# ATSAMR21E18A device description
Architecture: CORTEX-M0PLUS; Family: SAMR; Series: SAMR21
Registers are 32-bit, read-write, reset 0x0 unless marked. A register's access mark holds for its fields unless they carry their own. Offsets are from the block's base; [hi:lo] are bit positions; lines under a group give offsets from that group; {n}, {i} and the like mark numbered series; 'fields as' and 'values as' point back to an identical list; <NAME> marks a mode.

## RFCTRL — RF233 control module
Instances: RFCTRL 0x42005400
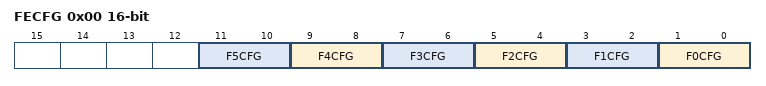
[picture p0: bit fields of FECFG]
0x00 FECFG 16-bit — Front-end control bus configuration
  [2n+1:2n] F{n}CFG (n=0..5) — Front-end control signal {n} configuration

## USB_DESCRIPTOR — Universal Serial Bus
Modes: DEVICE when USB.CTRLA.MODE=0 (USB is Device); HOST when USB.CTRLA.MODE=1 (USB is Host)
{0x0+0x10*i} DEVICE_DESC_BANK[{i}] (i=0..1) <DEVICE> group
  0x00 ADDR <DEVICE> reset not defined — DEVICE_DESC_BANK Endpoint Bank, Adress of Data Buffer
    [31:0] ADDR — Adress of data buffer
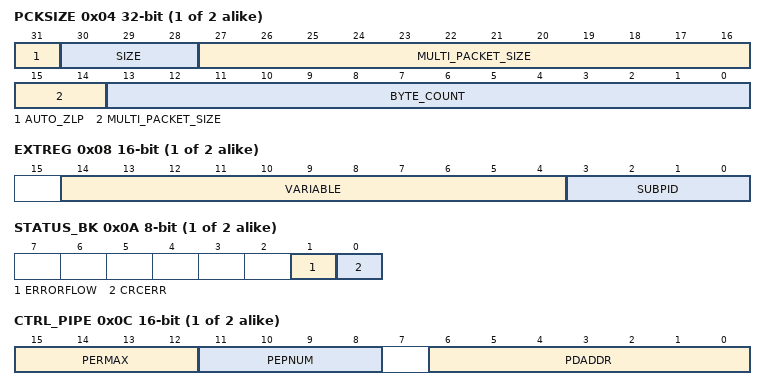
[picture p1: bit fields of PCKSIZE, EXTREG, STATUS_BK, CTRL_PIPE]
  0x04 PCKSIZE <DEVICE> reset not defined — DEVICE_DESC_BANK Endpoint Bank, Packet Size
    [31] AUTO_ZLP — Automatic Zero Length Packet
    [30:28] SIZE — Enpoint size
    [27:14] MULTI_PACKET_SIZE — Multi Packet In or Out size
    [13:0] BYTE_COUNT
  0x08 EXTREG <DEVICE> 16-bit reset not defined — DEVICE_DESC_BANK Endpoint Bank, Extended
    [14:4] VARIABLE — Variable field send with extended token
    [3:0] SUBPID — SUBPID field send with extended token
  0x0A STATUS_BK <DEVICE> 8-bit reset not defined — DEVICE_DESC_BANK Enpoint Bank, Status of Bank
    [1] ERRORFLOW — Error Flow Status
    [0] CRCERR — CRC Error Status
{0x0+0x10*i} HOST_DESC_BANK[{i}] (i=0..1) <HOST> group
  0x00 ADDR <HOST> reset not defined — HOST_DESC_BANK Host Bank, Adress of Data Buffer
    [31:0] ADDR — Adress of data buffer
  0x04 PCKSIZE <HOST> reset not defined — HOST_DESC_BANK Host Bank, Packet Size
    [31] AUTO_ZLP — Automatic Zero Length Packet
    [30:28] SIZE — Pipe size
    [27:14] MULTI_PACKET_SIZE — Multi Packet In or Out size
    [13:0] BYTE_COUNT
  0x08 EXTREG <HOST> 16-bit reset not defined — HOST_DESC_BANK Host Bank, Extended
    fields as DEVICE_DESC_BANK[0]<DEVICE>.EXTREG<DEVICE>
  0x0A STATUS_BK <HOST> 8-bit reset not defined — HOST_DESC_BANK Host Bank, Status of Bank
    [1] ERRORFLOW — Error Flow Status
    [0] CRCERR — CRC Error Status
  0x0C CTRL_PIPE <HOST> 16-bit — HOST_DESC_BANK Host Bank, Host Control Pipe
    [15:12] PERMAX — Pipe Error Max Number
    [11:8] PEPNUM — Pipe Endpoint Number
    [6:0] PDADDR — Pipe Device Adress
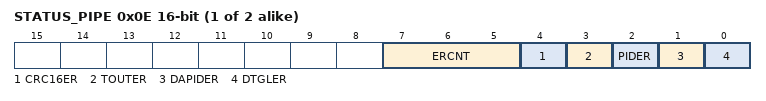
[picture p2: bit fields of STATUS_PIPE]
  0x0E STATUS_PIPE <HOST> 16-bit reset not defined — HOST_DESC_BANK Host Bank, Host Status Pipe
    [7:5] ERCNT — Pipe Error Count
    [4] CRC16ER — CRC16 Error
    [3] TOUTER — Time Out Error
    [2] PIDER — PID Error
    [1] DAPIDER — Data PID Error
    [0] DTGLER — Data Toggle Error

## WDT — Watchdog Timer
Instances: WDT 0x40001000
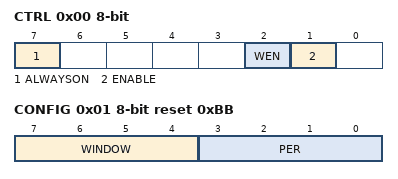
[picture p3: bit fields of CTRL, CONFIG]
0x00 CTRL 8-bit (WSYNC) — Control
  [7] ALWAYSON
  [2] WEN — Watchdog Timer Window Mode Enable
  [1] ENABLE
0x01 CONFIG 8-bit reset 0xBB (WSYNC) — Configuration
  [7:4] WINDOW — Window Mode Time-Out Period
    0=8 clock cycles; 1=16 clock cycles; 2=32 clock cycles; 3=64 clock cycles; 4=128 clock cycles; 5=256 clock cycles; 6=512 clock cycles; 7=1K (1024 clock cycles); 8=2K (2048 clock cycles); 9=4K (4096 clock cycles); 10=8K (8192 clock cycles); 11=16K (16384 clock cycles)
  [3:0] PER — Time-Out Period
    values as WINDOW
0x02 EWCTRL 8-bit reset 0xB — Early Warning Interrupt Control
  [3:0] EWOFFSET — Early Warning Interrupt Time Offset
    values as CONFIG.WINDOW
0x04 INTENCLR 8-bit (atomic clear) — Interrupt Enable Clear
  [0] EW — Early Warning Interrupt Enable
0x05 INTENSET 8-bit (atomic set) — Interrupt Enable Set
  [0] EW — Early Warning Interrupt Enable
0x06 INTFLAG 8-bit (atomic clear) — Interrupt Flag Status and Clear
  [0] EW — Early Warning
0x07 STATUS 8-bit ro
  [7] SYNCBUSY — Synchronization Busy
0x08 CLEAR 8-bit wo (WSYNC)
  [7:0] CLEAR — Watchdog Clear
    165=KEY (Clear Key)

## NVIC — Nested Vectored Interrupt Controller
Instances: NVIC 0xE000E100
0x00 ISER — Interrupt Set Enable Register
  [27:0] SETENA — Interrupt set enable bits
0x80 ICER — Interrupt Clear Enable Register
  [27:0] CLRENA — Interrupt clear-enable bits
0x100 ISPR — Interrupt Set Pending Register
  [27:0] SETPEND — Interrupt set-pending bits
0x180 ICPR — Interrupt Clear Pending Register
  [27:0] CLRPEND — Interrupt clear-pending bits
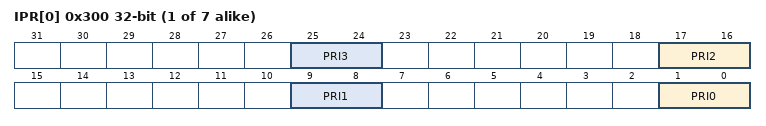
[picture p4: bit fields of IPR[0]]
{0x300+4i} IPR[{i}] (i=0..6) — Interrupt Priority Register n
  [8n+1:8n] PRI{n} (n=0..3) — Priority of interrupt n

## Notices in the file
Copyright (c) 2018 Microchip Technology Inc.
SPDX-License-Identifier: Apache-2.0
Licensed under the Apache License, Version 2.0 (the "License");
you may not use this file except in compliance with the License.
You may obtain a copy of the License at
http://www.apache.org/licenses/LICENSE-2.0
Unless required by applicable law or agreed to in writing, software
distributed under the License is distributed on an "AS IS" BASIS,
WITHOUT WARRANTIES OR CONDITIONS OF ANY KIND, either express or implied.
See the License for the specific language governing permissions and
limitations under the License.
